# Basic_Timer___RTC_1 register map
Vendor: Texas Instruments
Peripheral module from a debugger description file (folder msp430).
Registers are 8-bit, access not given, no defined reset value unless marked. A register's access mark holds for its fields unless they carry their own. Offsets are as the file gives them; lines under a group give offsets from that group; [hi:lo] are bit positions; {n}, {i} and the like mark numbered series; 'fields as' and 'values as' point back to an identical list; <NAME> marks a mode.

## Basic_Timer_/_RTC
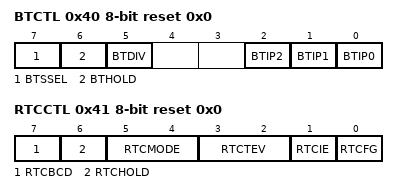
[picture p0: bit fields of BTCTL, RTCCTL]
0x40 BTCTL rw reset 0x0 — Basic Timer Control
  [7] BTSSEL — fBT = fMCLK (main clock)
  [6] BTHOLD — BT1 is held if this bit is set
  [5] BTDIV — fCLK2 = ACLK:256
  [2] BTIP2
  [1] BTIP1
  [0] BTIP0
0x40 RTCTL 16-bit — Basic/Real Timer Control
0x41 RTCCTL rw reset 0x0 — Real Time Clock Control
  [7] RTCBCD — RTC BCD Select
  [6] RTCHOLD
  [5:4] RTCMODE — RTC Mode 1
  [3:2] RTCTEV — RTC Time Event 1
    {v}=RTC Time Event: {v} (v=0..3)
  [1] RTCIE — RTC Interrupt Enable
  [0] RTCFG — RTC Event Flag
{0x41+i} RTCNT{i} (i=1..4) — Real Time Counter {i}
0x42 RTCTIM0 16-bit — Real Time Clock Time 0
0x44 RTCTIM1 16-bit — Real Time Clock Time 1
0x46 BTCNT1 — Basic Timer Count 1
0x46 BTCNT12 16-bit — Basic Timer Count 1/2
0x47 BTCNT2 — Basic Timer Count 2
0x4C RTCDAY — Real Time Clock Day
0x4C RTCDATE 16-bit — Real Time Clock Date
0x4D RTCMON — Real Time Clock Month
0x4E RTCYEARL — Real Time Clock Year (Low Byte)
0x4E RTCYEAR 16-bit — Real Time Clock Year
0x4F RTCYEARH — Real Time Clock Year (High Byte)
